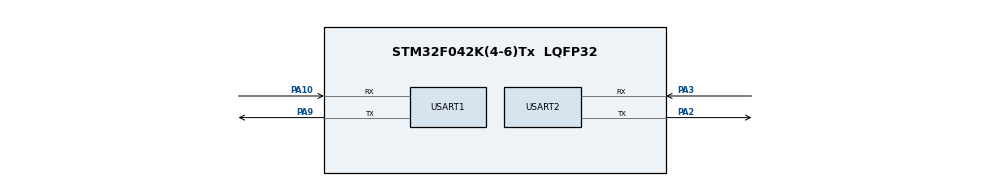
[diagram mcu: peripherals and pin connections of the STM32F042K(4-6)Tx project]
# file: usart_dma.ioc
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Mcu.Family=STM32F0
Dma.USART2_TX.1.Priority=DMA_PRIORITY_LOW
Dma.USART1_RX.0.PeriphDataAlignment=DMA_PDATAALIGN_BYTE
PA10.Mode=Asynchronous
Dma.USART2_TX.1.MemInc=DMA_MINC_ENABLE
USART1.WordLength=WORDLENGTH_8B
Dma.USART2_TX.1.PeriphDataAlignment=DMA_PDATAALIGN_BYTE
ProjectManager.StackSize=0x400
USART1.VirtualMode-Asynchronous=VM_ASYNC
PA3.Mode=Asynchronous
PA9.Mode=Asynchronous
ProjectManager.TargetToolchain=SW4STM32
Dma.USART1_RX.0.Direction=DMA_PERIPH_TO_MEMORY
PA9.Signal=USART1_TX
Dma.USART2_TX.1.Mode=DMA_CIRCULAR
Dma.USART1_RX.0.PeriphInc=DMA_PINC_DISABLE
Dma.USART1_RX.0.Priority=DMA_PRIORITY_LOW
Dma.USART2_TX.1.PeriphInc=DMA_PINC_DISABLE
board=usart_dma
USART2.VirtualMode-Asynchronous=VM_ASYNC
NVIC.DMA1_Channel4_5_IRQn=true\:0\:0\:false\:false\:true\:false\:true
Dma.USART2_TX.1.Direction=DMA_MEMORY_TO_PERIPH
Dma.USART2_TX.1.Instance=DMA1_Channel4
Dma.USART1_RX.0.MemDataAlignment=DMA_MDATAALIGN_BYTE
Dma.USART1_RX.0.MemInc=DMA_MINC_ENABLE
Mcu.Name=STM32F042K(4-6)Tx
PA2.Signal=USART2_TX
Mcu.Package=LQFP32
PA10.Signal=USART1_RX
ProjectManager.HeapSize=0x200
USART2.WordLength=WORDLENGTH_8B
NVIC.DMA1_Channel2_3_IRQn=true\:0\:0\:false\:false\:true\:false\:true
Dma.Request1=USART2_TX
PA2.Mode=Asynchronous
Dma.USART1_RX.0.Mode=DMA_NORMAL
Dma.USART2_TX.1.MemDataAlignment=DMA_MDATAALIGN_BYTE
Dma.Request0=USART1_RX
Dma.USART1_RX.0.Instance=DMA1_Channel3
PA3.Signal=USART2_RX

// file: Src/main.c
/* USER CODE BEGIN Header */
/**
  ******************************************************************************
  * @file           : main.c
  * @brief          : Main program body
  ******************************************************************************
  * @attention
  *
  * <h2><center>&copy; Copyright (c) 2020 STMicroelectronics.
  * All rights reserved.</center></h2>
  *
  * This software component is licensed by ST under BSD 3-Clause license,
  * the "License"; You may not use this file except in compliance with the
  * License. You may obtain a copy of the License at:
  *                        opensource.org/licenses/BSD-3-Clause
  *
  ******************************************************************************
  */
/* USER CODE END Header */

#include "main.h"

/* USER CODE BEGIN Includes */
#include <assert.h>
/* USER CODE END Includes */

UART_HandleTypeDef huart1;
UART_HandleTypeDef huart2;
DMA_HandleTypeDef hdma_usart1_rx;
DMA_HandleTypeDef hdma_usart2_tx;

/* USER CODE BEGIN PV */
/* Private variables ---------------------------------------------------------*/

/* USER CODE END PV */

void SystemClock_Config(void);
static void MX_GPIO_Init(void);
static void MX_DMA_Init(void);
static void MX_USART1_UART_Init(void);
static void MX_USART2_UART_Init(void);
/* USER CODE BEGIN PFP */
/* Private function prototypes -----------------------------------------------*/

/* USER CODE END PFP */

/* USER CODE BEGIN 0 */

#define BUFFER_SIZE 128

uint8_t buffer[BUFFER_SIZE] = { 0 };

//  see https://community.st.com/s/question/0D50X00009XkXbj/stm32f091rc-i2c-dma-transfer-complete
void HAL_UART_RxCpltCallback(UART_HandleTypeDef* huart) {
    assert(huart == &huart1);
    assert(HAL_UART_Transmit_DMA(&huart2, buffer, BUFFER_SIZE) == HAL_OK);
}

void HAL_UART_TxCpltCallback(UART_HandleTypeDef* huart) {
    assert(huart == &huart2);
    // we should disable DMA on huart2 before new receive because DMAStop clear ISR register
    assert(HAL_UART_DMAStop(&huart2) == HAL_OK);
    assert(HAL_UART_Receive_DMA(&huart1, buffer, BUFFER_SIZE) == HAL_OK);
}

/* USER CODE END 0 */

int main(void)
{

  /* MCU Configuration--------------------------------------------------------*/

  /* Reset of all peripherals, Initializes the Flash interface and the Systick. */
  HAL_Init();

  /* Configure the system clock */
  SystemClock_Config();

  /* Initialize all configured peripherals */
  MX_GPIO_Init();
  MX_DMA_Init();
  MX_USART1_UART_Init();
  MX_USART2_UART_Init();
  /* USER CODE BEGIN 2 */

  assert(HAL_UART_Receive_DMA(&huart1, buffer, BUFFER_SIZE) == HAL_OK);

  /* USER CODE END 2 */

  /* Infinite loop */
  while (1)
  {

  }
}

void SystemClock_Config(void)
{
  RCC_OscInitTypeDef RCC_OscInitStruct = {0};
  RCC_ClkInitTypeDef RCC_ClkInitStruct = {0};
  RCC_PeriphCLKInitTypeDef PeriphClkInit = {0};

  /** Initializes the CPU, AHB and APB busses clocks
  */
  RCC_OscInitStruct.OscillatorType = RCC_OSCILLATORTYPE_HSI;
  RCC_OscInitStruct.HSIState = RCC_HSI_ON;
  RCC_OscInitStruct.HSICalibrationValue = RCC_HSICALIBRATION_DEFAULT;
  RCC_OscInitStruct.PLL.PLLState = RCC_PLL_NONE;
  if (HAL_RCC_OscConfig(&RCC_OscInitStruct) != HAL_OK)
  {
    Error_Handler();
  }
  /** Initializes the CPU, AHB and APB busses clocks
  */
  RCC_ClkInitStruct.ClockType = RCC_CLOCKTYPE_HCLK|RCC_CLOCKTYPE_SYSCLK
                              |RCC_CLOCKTYPE_PCLK1;
  RCC_ClkInitStruct.SYSCLKSource = RCC_SYSCLKSOURCE_HSI;
  RCC_ClkInitStruct.AHBCLKDivider = RCC_SYSCLK_DIV1;
  RCC_ClkInitStruct.APB1CLKDivider = RCC_HCLK_DIV1;

  if (HAL_RCC_ClockConfig(&RCC_ClkInitStruct, FLASH_LATENCY_0) != HAL_OK)
  {
    Error_Handler();
  }
  PeriphClkInit.PeriphClockSelection = RCC_PERIPHCLK_USART1;
  PeriphClkInit.Usart1ClockSelection = RCC_USART1CLKSOURCE_PCLK1;
  if (HAL_RCCEx_PeriphCLKConfig(&PeriphClkInit) != HAL_OK)
  {
    Error_Handler();
  }
}

static void MX_USART1_UART_Init(void)
{

  huart1.Instance = USART1;
  huart1.Init.BaudRate = 38400;
  huart1.Init.WordLength = UART_WORDLENGTH_8B;
  huart1.Init.StopBits = UART_STOPBITS_1;
  huart1.Init.Parity = UART_PARITY_NONE;
  huart1.Init.Mode = UART_MODE_TX_RX;
  huart1.Init.HwFlowCtl = UART_HWCONTROL_NONE;
  huart1.Init.OverSampling = UART_OVERSAMPLING_16;
  huart1.Init.OneBitSampling = UART_ONE_BIT_SAMPLE_DISABLE;
  huart1.AdvancedInit.AdvFeatureInit = UART_ADVFEATURE_NO_INIT;
  if (HAL_UART_Init(&huart1) != HAL_OK)
  {
    Error_Handler();
  }

}

static void MX_USART2_UART_Init(void)
{

  huart2.Instance = USART2;
  huart2.Init.BaudRate = 38400;
  huart2.Init.WordLength = UART_WORDLENGTH_8B;
  huart2.Init.StopBits = UART_STOPBITS_1;
  huart2.Init.Parity = UART_PARITY_NONE;
  huart2.Init.Mode = UART_MODE_TX_RX;
  huart2.Init.HwFlowCtl = UART_HWCONTROL_NONE;
  huart2.Init.OverSampling = UART_OVERSAMPLING_16;
  huart2.Init.OneBitSampling = UART_ONE_BIT_SAMPLE_DISABLE;
  huart2.AdvancedInit.AdvFeatureInit = UART_ADVFEATURE_NO_INIT;
  if (HAL_UART_Init(&huart2) != HAL_OK)
  {
    Error_Handler();
  }

}

static void MX_DMA_Init(void)
{

  /* DMA controller clock enable */
  __HAL_RCC_DMA1_CLK_ENABLE();

  /* DMA interrupt init */
  /* DMA1_Channel2_3_IRQn interrupt configuration */
  HAL_NVIC_SetPriority(DMA1_Channel2_3_IRQn, 0, 0);
  HAL_NVIC_EnableIRQ(DMA1_Channel2_3_IRQn);
  /* DMA1_Channel4_5_IRQn interrupt configuration */
  HAL_NVIC_SetPriority(DMA1_Channel4_5_IRQn, 0, 0);
  HAL_NVIC_EnableIRQ(DMA1_Channel4_5_IRQn);

}

static void MX_GPIO_Init(void)
{

  /* GPIO Ports Clock Enable */
  __HAL_RCC_GPIOA_CLK_ENABLE();

}

void Error_Handler(void)
{
  while(1)
  {
  }
}

/************************ (C) COPYRIGHT STMicroelectronics *****END OF FILE****/
